AUTOSAR XML (schema 00050)
package /STLASWCs
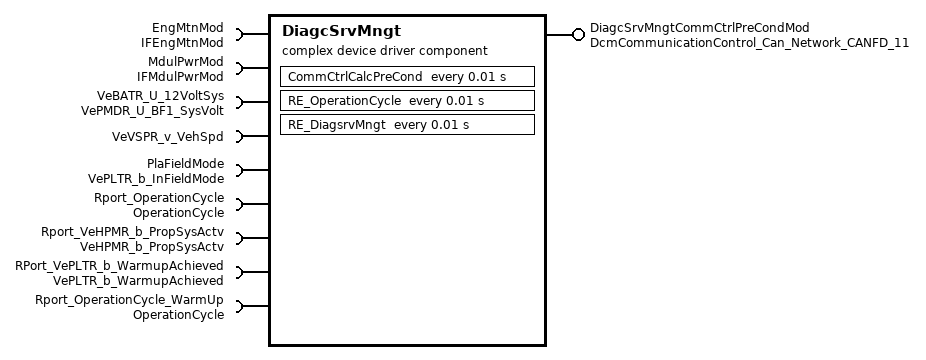
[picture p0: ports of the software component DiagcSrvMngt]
  complex device driver sw component type DiagcSrvMngt  # Diagnostic Service Managemnet Component - Interfaces with DCM and is responsible to handle ECU Reset request, Communication Control request and callouts for Read and Write Memory By Address.
    provide port DiagcSrvMngtCommCtrlPreCondMod: provided-interface=DcmCommunicationControl_Can_Network_CANFD_11  # This a mode port used to determine if the preconditions are met or not met to disable transmission for communication control service
    9 x require port:
      EngMtnMod: mode-switch-receiver-com-spec=EngMtnMod, required-interface=IFEngMtnMod  # Engine motion modes for Comm Pre control conditions (1 - EngStopd, 0 - EngMovg)
      MdulPwrMod: required-interface=IFMdulPwrMod
      VeBATR_U_12VoltSys: required-interface=VePMDR_U_BF1_SysVolt  # Voltage for 12 Volt (Nominal) System, with filtering and plausibility checks needed for general usage (Legacy Signal Name - BATTERY_VOLTAGE_FILTERED)
      VeVSPR_v_VehSpd: required-interface=VeVSPR_v_VehSpd  # Vehicle Speed Estimator
      PlaFieldMode: required-interface=VePLTR_b_InFieldMode  # Port to decide plant or field mode condition (1 - InPla, 0 - InFie)
      Rport_OperationCycle: required-interface=OperationCycle
      Rport_VeHPMR_b_PropSysActv: required-interface=VeHPMR_b_PropSysActv
      RPort_VePLTR_b_WarmupAchieved: nonqueued-receiver-com-spec{data-element=Value, handle-never-received=true, init-value=0}, required-interface=VePLTR_b_WarmupAchieved
      Rport_OperationCycle_WarmUp: required-interface=OperationCycle
    behavior IBDiagcSrvMngt: data-type-mapping=[BswMMappingSet, DTS_DcmDiagnosticSessionControl, DTS_DcmEcuReset, DTS_DcmControlDTCSetting, DTS_EngMtnMods, DTS_DcmCommunicationControl_Can_Network_CANFD_3, DTS_DcmCommunicationControl_Can_Network_CANFD_11, ADTtoIDTMapping, ADTtoIDTMapping], handle-termination-and-restart=NO-SUPPORT
      timing event MedTEA1: disabled-mode=[MdulPwrMod.AppMode_MDGP_ESH_Mode.POSTRUN, MdulPwrMod.AppMode_MDGP_ESH_Mode.SHUTDOWN], start-on-event=CommCtrlCalcPreCond, period=0.01
      timing event TimingEvent_0: start-on-event=RE_OperationCycle, period=0.01
      timing event TimingEvent_1: start-on-event=RE_DiagsrvMngt, period=0.01
      runnable CommCtrlCalcPreCond: symbol=DiagcSrvMngt_CommCtrlCalcPreCond  # Runnable tied to cyclic event which sets the mode based on precondition checks to disable transmission
        data-receive-point-by-arguments:
          access DRP_VeVSPR_v_VehSpd_VeVSPR_v_VehSpd: accessed-variable=VeVSPR_v_VehSpd.VeVSPR_v_VehSpd
        mode-access-point mode-group=EngMtnMod.EngMtnMod:
          ident MAP_EngMtnMod_EngMtnMod
        mode-access-point mode-group=MdulPwrMod.AppMode_MDGP_ESH_Mode:
          ident MAP_Switch_ESH_ModeSwitch_BswM_MDGP_ESH_Mode
        mode switch point MSP_DiagcSrvMngtCommCtrlPreCondMod_MDGP_DcmCommunicationControl_ComMChannel_Can_Network_CANFD_3_Channel: mode-group=DiagcSrvMngtCommCtrlPreCondMod.MDGP_DcmCommunicationControl_Can_Network_CANFD_11
      runnable RE_OperationCycle: symbol=RE_OperationCycle_func
        data-receive-point-by-arguments:
          access DataReceivePointByArguments_VariableAccess_0: accessed-variable=RPort_VePLTR_b_WarmupAchieved.Value
        5 x sync call:
          SynchronousServerCallPoint_0: operation=Rport_OperationCycle.RestartOperationCycle
          SynchronousServerCallPoint_1: operation=Rport_OperationCycle.GetCycleQualified
          SynchronousServerCallPoint_2: operation=Rport_OperationCycle.SetCycleQualified
          SynchronousServerCallPoint_0_Copy: operation=Rport_OperationCycle_WarmUp.RestartOperationCycle
          SynchronousServerCallPoint_2_Copy: operation=Rport_OperationCycle_WarmUp.SetCycleQualified
      runnable RE_DiagsrvMngt: symbol=RE_DiagsrvMngt_func
        data-receive-point-by-arguments:
          access VeHPMR_PropSysActv: accessed-variable=Rport_VeHPMR_b_PropSysActv.Value
